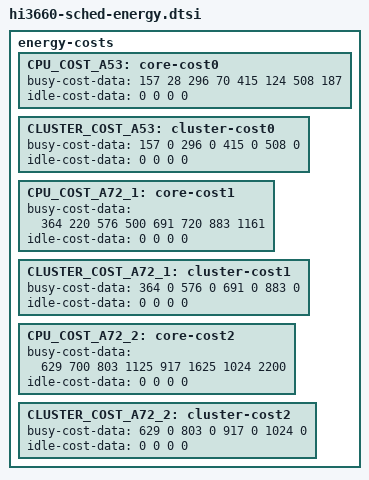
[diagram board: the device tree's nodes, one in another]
/*
 * Hi3660 specific energy cost model data. There are no unit
 * requirements for the data. Data can be normalized to any
 * reference point, but the normalization must be consistent.
 * That is, one bogo-joule/watt must be the same quantity for
 * all data, but we don't care what it is.
 */

energy-costs {
	//Littles
	CPU_COST_A53: core-cost0 {
		busy-cost-data = <
			157 28
			296 70
			415 124
			508 187
		>;
		idle-cost-data = <
			0
			0
			0
			0
		>;
	};
	CLUSTER_COST_A53: cluster-cost0 {
		busy-cost-data = <
			157 0
			296 0
			415 0
			508 0
		>;
		idle-cost-data = <
			0
			0
			0
			0
		>;
	};

	//Mediums
	CPU_COST_A72_1: core-cost1 {
		busy-cost-data = <
			364 220
			576 500
			691 720
			883 1161
		>;
		idle-cost-data = <
			0
			0
			0
			0
		>;
	};
	CLUSTER_COST_A72_1: cluster-cost1 {
		busy-cost-data = <
			364 0
			576 0
			691 0
			883 0
		>;
		idle-cost-data = <
			0
			0
			0
			0
		>;
	};

	//Bigs
	CPU_COST_A72_2: core-cost2 {
		busy-cost-data = <
			629 700
			803 1125
			917 1625
			1024 2200
		>;
		idle-cost-data = <
			0
			0
			0
			0
		>;
	};
	CLUSTER_COST_A72_2: cluster-cost2 {
		busy-cost-data = <
			629 0
			803 0
			917 0
			1024 0
		>;
		idle-cost-data = <
			0
			0
			0
			0
		>;
	};
};
